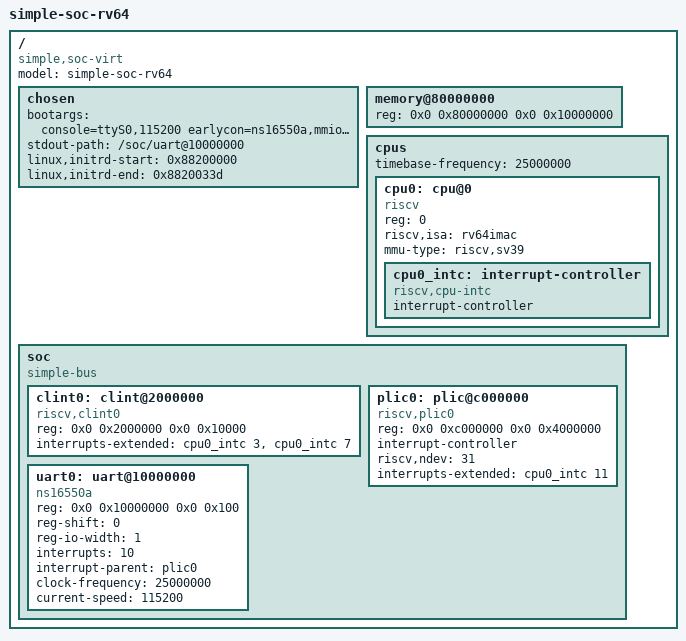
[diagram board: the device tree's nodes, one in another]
/dts-v1/;

/*
 * Device tree for the landed Simple RV64 SoC (src/lib/hardware/soc_rtl/).
 *
 * Matches the SoC exactly as of soc_top_64.spl:
 *   - 1 hart, rv64imac (M-mode; S-mode is Lane M in-flight)
 *   - RAM     @ 0x8000_0000  (size below must match dram_size passed to
 *                             soc_top_64_init; manifest default = 128 MiB)
 *   - CLINT   @ 0x0200_0000  (msip / mtimecmp / mtime)
 *   - PLIC    @ 0x0C00_0000  (riscv,plic0; 32 sources -> ndev = 31;
 *                             ONE context = context 0, M-mode only)
 *   - UART    @ 0x1000_0000  (ns16550a, byte-wide regs, PLIC source 10)
 *
 * Boot chain (see bootrom_read64 in soc_rtl/bootrom.spl):
 *   bootrom @ 0x1000 sets a1 = 0x8800_0000 (THIS blob's load address) and
 *   jumps to 0x8000_0000 (OpenSBI fw_jump), which enters the kernel at
 *   0x8020_0000 with a1 still pointing at the DTB.
 *
 * TODO(laneN-clock): clock-frequency + timebase-frequency below use the
 * candidate 25 MHz value (core must close timing <= ~33 MHz per the WNS
 * probe; Lane N owns the final XDC clock decision). Update BOTH values,
 * and re-run dtc, once Lane N lands the real PL clock.
 */

/ {
	#address-cells = <2>;
	#size-cells = <2>;
	compatible = "simple,soc-virt";
	model = "simple-soc-rv64";

	chosen {
		bootargs = "console=ttyS0,115200 earlycon=ns16550a,mmio,0x10000000";
		stdout-path = "/soc/uart@10000000";
		/*
		 * initrd wiring so a *static* -dtb boot finds the initramfs. The
		 * bootrom puts the FDT at 0x88000000, so the initramfs sits just
		 * above it. These are what QEMU computes for the pinned initramfs
		 * (build_rv64_linux_assets.shs); initrd-end = start + initramfs size,
		 * so rebuild the DTB if the initramfs changes. Without these a static
		 * -dtb cannot advertise the initrd and Linux panics "VFS: Unable to
		 * mount root fs".
		 */
		linux,initrd-start = <0x88200000>;
		linux,initrd-end   = <0x8820033d>;
	};

	memory@80000000 {
		device_type = "memory";
		/*
		 * 256 MiB. The bootrom places the FDT at 0x88000000 (the exclusive
		 * top edge of a 128 MiB map) and the initramfs sits just above it, so
		 * a full OpenSBI+Linux boot needs RAM past 0x88000000 (128 MiB is too
		 * small — OpenSBI faults on the edge FDT). Pass this same size as
		 * dram_size to soc_top_64_init when the RTL grows a Linux boot.
		 */
		reg = <0x0 0x80000000 0x0 0x10000000>;
	};

	cpus {
		#address-cells = <1>;
		#size-cells = <0>;
		/* TODO(laneN-clock): candidate 25 MHz; CLINT mtime ticks once
		 * per core clock, so timebase == core clock frequency. */
		timebase-frequency = <25000000>;

		cpu0: cpu@0 {
			device_type = "cpu";
			reg = <0>;
			status = "okay";
			compatible = "riscv";
			riscv,isa = "rv64imac";
			/* Sv39 pends on Lane M S-mode landing; harmless for
			 * OpenSBI/M-mode, required before Linux paging works. */
			mmu-type = "riscv,sv39";

			cpu0_intc: interrupt-controller {
				#interrupt-cells = <1>;
				interrupt-controller;
				compatible = "riscv,cpu-intc";
			};
		};
	};

	soc {
		#address-cells = <2>;
		#size-cells = <2>;
		compatible = "simple-bus";
		ranges;

		clint0: clint@2000000 {
			compatible = "riscv,clint0";
			reg = <0x0 0x2000000 0x0 0x10000>;
			/* 3 = M-mode software irq (msip), 7 = M-mode timer irq */
			interrupts-extended = <&cpu0_intc 3 &cpu0_intc 7>;
		};

		plic0: plic@c000000 {
			compatible = "riscv,plic0";
			reg = <0x0 0xc000000 0x0 0x4000000>;
			#address-cells = <0>;
			#interrupt-cells = <1>;
			interrupt-controller;
			/* soc_rtl plic.spl: 32 sources, source 0 hardwired 0 */
			riscv,ndev = <31>;
			/* ONE context (context 0 = M-mode ext irq 11). The RTL
			 * has no S-mode context yet — Linux irq delivery needs
			 * a context claiming S-ext (9); see guide doc gap G2. */
			interrupts-extended = <&cpu0_intc 11>;
		};

		uart0: uart@10000000 {
			compatible = "ns16550a";
			reg = <0x0 0x10000000 0x0 0x100>;
			/* Byte-wide registers at byte offsets (IER=+1, LSR=+5) */
			reg-shift = <0>;
			reg-io-width = <1>;
			/* PLIC source 10 */
			interrupts = <10>;
			interrupt-parent = <&plic0>;
			/* TODO(laneN-clock): candidate 25 MHz — must equal the
			 * real UART input clock for divisor/baud 115200. */
			clock-frequency = <25000000>;
			current-speed = <115200>;
			status = "okay";
		};
	};
};
